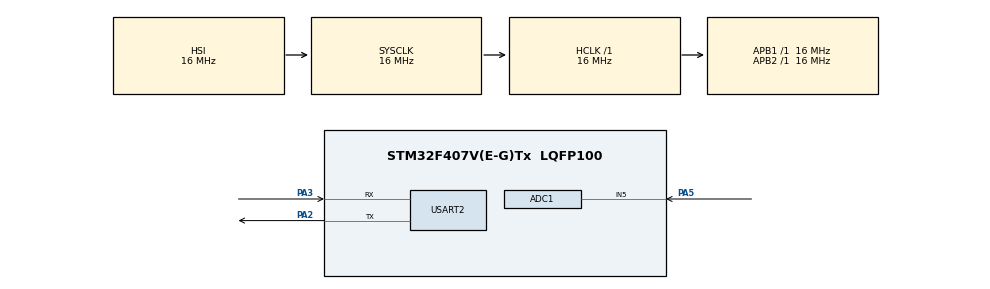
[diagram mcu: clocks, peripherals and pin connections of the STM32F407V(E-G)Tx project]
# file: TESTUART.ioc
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ADC1.Channel-0\#ChannelRegularConversion=ADC_CHANNEL_5
ADC1.ContinuousConvMode=ENABLE
ADC1.DMAContinuousRequests=ENABLE
ADC1.NbrOfConversionFlag=1
ADC1.Rank-0\#ChannelRegularConversion=1
ADC1.SamplingTime-0\#ChannelRegularConversion=ADC_SAMPLETIME_3CYCLES
ADC1.master=1
Dma.ADC1.2.Direction=DMA_PERIPH_TO_MEMORY
Dma.ADC1.2.FIFOMode=DMA_FIFOMODE_DISABLE
Dma.ADC1.2.Instance=DMA2_Stream0
Dma.ADC1.2.MemDataAlignment=DMA_MDATAALIGN_HALFWORD
Dma.ADC1.2.MemInc=DMA_MINC_ENABLE
Dma.ADC1.2.Mode=DMA_NORMAL
Dma.ADC1.2.PeriphDataAlignment=DMA_PDATAALIGN_HALFWORD
Dma.ADC1.2.PeriphInc=DMA_PINC_DISABLE
Dma.ADC1.2.Priority=DMA_PRIORITY_LOW
Dma.Request0=USART2_TX
Dma.Request1=USART2_RX
Dma.Request2=ADC1
Dma.USART2_RX.1.Direction=DMA_PERIPH_TO_MEMORY
Dma.USART2_RX.1.FIFOMode=DMA_FIFOMODE_DISABLE
Dma.USART2_RX.1.Instance=DMA1_Stream5
Dma.USART2_RX.1.MemDataAlignment=DMA_MDATAALIGN_BYTE
Dma.USART2_RX.1.MemInc=DMA_MINC_ENABLE
Dma.USART2_RX.1.Mode=DMA_NORMAL
Dma.USART2_RX.1.PeriphDataAlignment=DMA_PDATAALIGN_BYTE
Dma.USART2_RX.1.PeriphInc=DMA_PINC_DISABLE
Dma.USART2_RX.1.Priority=DMA_PRIORITY_LOW
Dma.USART2_TX.0.Direction=DMA_MEMORY_TO_PERIPH
Dma.USART2_TX.0.FIFOMode=DMA_FIFOMODE_DISABLE
Dma.USART2_TX.0.Instance=DMA1_Stream6
Dma.USART2_TX.0.MemDataAlignment=DMA_MDATAALIGN_BYTE
Dma.USART2_TX.0.MemInc=DMA_MINC_ENABLE
Dma.USART2_TX.0.Mode=DMA_NORMAL
Dma.USART2_TX.0.PeriphDataAlignment=DMA_PDATAALIGN_BYTE
Dma.USART2_TX.0.PeriphInc=DMA_PINC_DISABLE
Dma.USART2_TX.0.Priority=DMA_PRIORITY_LOW
Mcu.Family=STM32F4
Mcu.Name=STM32F407V(E-G)Tx
Mcu.Package=LQFP100
NVIC.DMA1_Stream5_IRQn=true\:0\:0\:false\:false\:true\:false\:true
NVIC.DMA1_Stream6_IRQn=true\:0\:0\:false\:false\:true\:false\:true
NVIC.DMA2_Stream0_IRQn=true\:0\:0\:false\:false\:true\:false\:true
NVIC.PriorityGroup=NVIC_PRIORITYGROUP_4
PA2.Mode=Asynchronous
PA2.Signal=USART2_TX
PA3.Mode=Asynchronous
PA3.Signal=USART2_RX
PA5.Signal=ADCx_IN5
ProjectManager.HeapSize=0x200
ProjectManager.StackSize=0x400
ProjectManager.TargetToolchain=MDK-ARM V5.27
RCC.AHBFreq_Value=16000000
RCC.APB1Freq_Value=16000000
RCC.APB2Freq_Value=16000000
RCC.CortexFreq_Value=16000000
RCC.HSE_VALUE=25000000
RCC.HSI_VALUE=16000000
RCC.LSE_VALUE=32768
RCC.SYSCLKFreq_VALUE=16000000
RCC.VCOOutputFreq_Value=192000000
SH.ADCx_IN5.0=ADC1_IN5,IN5
USART2.VirtualMode=VM_ASYNC
board=custom

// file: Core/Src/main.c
/* USER CODE BEGIN Header */
/**
  ******************************************************************************
  * @file           : main.c
  * @brief          : Main program body
  ******************************************************************************
  * @attention
  *
  * <h2><center>&copy; Copyright (c) 2021 STMicroelectronics.
  * All rights reserved.</center></h2>
  *
  * This software component is licensed by ST under BSD 3-Clause license,
  * the "License"; You may not use this file except in compliance with the
  * License. You may obtain a copy of the License at:
  *                        opensource.org/licenses/BSD-3-Clause
  *
  ******************************************************************************
  */
/* USER CODE END Header */
#include "main.h"
#include "stm32f4xx.h"
#include "stdio.h"
#include "string.h"
#include "stm32f4xx_hal.h"

ADC_HandleTypeDef hadc1;
DMA_HandleTypeDef hdma_adc1;

UART_HandleTypeDef huart2;
DMA_HandleTypeDef hdma_usart2_tx;
DMA_HandleTypeDef hdma_usart2_rx;

void SystemClock_Config(void);
static void MX_GPIO_Init(void);
static void MX_DMA_Init(void);
static void MX_USART2_UART_Init(void);
static void MX_ADC1_Init(void);

int main(void)
{
  /* USER CODE BEGIN 1 */
uint8_t str[] = "USART TRANSMIT\r\n";
uint8_t message[] = "Test_2";
  /* USER CODE END 1 */

	/////////////////////////////////////////////////////////////////////
	/////////////////////////////////////////////////////////////////////
  /* MCU Configuration--------------------------------------------------------*/

  /* Reset of all peripherals, Initializes the Flash interface and the Systick. */
  HAL_Init();

  /* Configure the system clock */
  SystemClock_Config();

  /* Initialize all configured peripherals */
  MX_GPIO_Init();
  MX_DMA_Init();
  MX_USART2_UART_Init();
  MX_ADC1_Init();

  /* Infinite loop */

	char trans_str[100];
	#define ADC_BUF_LEN 100
	uint16_t adc_buf[ADC_BUF_LEN];
	char tr[518];
	char trans_str1[64] ={0,};
uint16_t adc = 0;

	HAL_ADC_Start_DMA(&hadc1, (uint32_t*)adc_buf, ADC_BUF_LEN);

  while (1)
  {

		///////////checking adc

		//HAL_ADC_Start(&hadc1);// start ADC
		//HAL_ADC_PollForConversion(&hadc1,100); //waitig for ADC
		//adc = HAL_ADC_GetValue(&hadc1);
		//HAL_ADC_Stop(&hadc1);
		//if (adc > 10)
		//{

			//snprintf(trans_str1, 63, " ADC = %d \n\r", adc );
			//HAL_UART_Transmit(&huart2, (uint8_t*)trans_str1, strlen(trans_str1), 1000);
			//HAL_Delay(1);
		//}

		snprintf(trans_str, 100, " ADC(u) = %u \n\r",adc_buf[0] );
			HAL_UART_Transmit(&huart2, (uint8_t*)trans_str, strlen(trans_str), 0xFFFF);
		HAL_Delay(1000);
  }
}

void SystemClock_Config(void)
{
  RCC_OscInitTypeDef RCC_OscInitStruct = {0};
  RCC_ClkInitTypeDef RCC_ClkInitStruct = {0};

  /** Configure the main internal regulator output voltage
  */
  __HAL_RCC_PWR_CLK_ENABLE();
  __HAL_PWR_VOLTAGESCALING_CONFIG(PWR_REGULATOR_VOLTAGE_SCALE1);
  /** Initializes the RCC Oscillators according to the specified parameters
  * in the RCC_OscInitTypeDef structure.
  */
  RCC_OscInitStruct.OscillatorType = RCC_OSCILLATORTYPE_HSI;
  RCC_OscInitStruct.HSIState = RCC_HSI_ON;
  RCC_OscInitStruct.HSICalibrationValue = RCC_HSICALIBRATION_DEFAULT;
  RCC_OscInitStruct.PLL.PLLState = RCC_PLL_NONE;
  if (HAL_RCC_OscConfig(&RCC_OscInitStruct) != HAL_OK)
  {
    Error_Handler();
  }
  /** Initializes the CPU, AHB and APB buses clocks
  */
  RCC_ClkInitStruct.ClockType = RCC_CLOCKTYPE_HCLK|RCC_CLOCKTYPE_SYSCLK
                              |RCC_CLOCKTYPE_PCLK1|RCC_CLOCKTYPE_PCLK2;
  RCC_ClkInitStruct.SYSCLKSource = RCC_SYSCLKSOURCE_HSI;
  RCC_ClkInitStruct.AHBCLKDivider = RCC_SYSCLK_DIV1;
  RCC_ClkInitStruct.APB1CLKDivider = RCC_HCLK_DIV1;
  RCC_ClkInitStruct.APB2CLKDivider = RCC_HCLK_DIV1;

  if (HAL_RCC_ClockConfig(&RCC_ClkInitStruct, FLASH_LATENCY_0) != HAL_OK)
  {
    Error_Handler();
  }
}

static void MX_ADC1_Init(void)
{

  ADC_ChannelConfTypeDef sConfig = {0};

  /** Configure the global features of the ADC (Clock, Resolution, Data Alignment and number of conversion)
  */
  hadc1.Instance = ADC1;
  hadc1.Init.ClockPrescaler = ADC_CLOCK_SYNC_PCLK_DIV2;
  hadc1.Init.Resolution = ADC_RESOLUTION_12B;
  hadc1.Init.ScanConvMode = DISABLE;
  hadc1.Init.ContinuousConvMode = ENABLE;
  hadc1.Init.DiscontinuousConvMode = DISABLE;
  hadc1.Init.ExternalTrigConvEdge = ADC_EXTERNALTRIGCONVEDGE_NONE;
  hadc1.Init.ExternalTrigConv = ADC_SOFTWARE_START;
  hadc1.Init.DataAlign = ADC_DATAALIGN_RIGHT;
  hadc1.Init.NbrOfConversion = 1;
  hadc1.Init.DMAContinuousRequests = ENABLE;
  hadc1.Init.EOCSelection = ADC_EOC_SINGLE_CONV;
  if (HAL_ADC_Init(&hadc1) != HAL_OK)
  {
    Error_Handler();
  }
  /** Configure for the selected ADC regular channel its corresponding rank in the sequencer and its sample time.
  */
  sConfig.Channel = ADC_CHANNEL_5;
  sConfig.Rank = 1;
  sConfig.SamplingTime = ADC_SAMPLETIME_3CYCLES;
  if (HAL_ADC_ConfigChannel(&hadc1, &sConfig) != HAL_OK)
  {
    Error_Handler();
  }

}

static void MX_USART2_UART_Init(void)
{

  huart2.Instance = USART2;
  huart2.Init.BaudRate = 115200;
  huart2.Init.WordLength = UART_WORDLENGTH_8B;
  huart2.Init.StopBits = UART_STOPBITS_1;
  huart2.Init.Parity = UART_PARITY_NONE;
  huart2.Init.Mode = UART_MODE_TX_RX;
  huart2.Init.HwFlowCtl = UART_HWCONTROL_NONE;
  huart2.Init.OverSampling = UART_OVERSAMPLING_16;
  if (HAL_UART_Init(&huart2) != HAL_OK)
  {
    Error_Handler();
  }

}

static void MX_DMA_Init(void)
{

  /* DMA controller clock enable */
  __HAL_RCC_DMA1_CLK_ENABLE();
  __HAL_RCC_DMA2_CLK_ENABLE();

  /* DMA interrupt init */
  /* DMA1_Stream5_IRQn interrupt configuration */
  HAL_NVIC_SetPriority(DMA1_Stream5_IRQn, 0, 0);
  HAL_NVIC_EnableIRQ(DMA1_Stream5_IRQn);
  /* DMA1_Stream6_IRQn interrupt configuration */
  HAL_NVIC_SetPriority(DMA1_Stream6_IRQn, 0, 0);
  HAL_NVIC_EnableIRQ(DMA1_Stream6_IRQn);
  /* DMA2_Stream0_IRQn interrupt configuration */
  HAL_NVIC_SetPriority(DMA2_Stream0_IRQn, 0, 0);
  HAL_NVIC_EnableIRQ(DMA2_Stream0_IRQn);

}

static void MX_GPIO_Init(void)
{

  /* GPIO Ports Clock Enable */
  __HAL_RCC_GPIOA_CLK_ENABLE();

}

void Error_Handler(void)
{
  __disable_irq();
  while (1)
  {
  }
}

/************************ (C) COPYRIGHT STMicroelectronics *****END OF FILE****/
